# MSPM0G320X register map
Vendor: Texas Instruments; File version: Revised: 2025-10-06 10:58:04
CPU: CM0 r0p1, little endian, MPU, no FPU, 3 interrupt priority bits
Registers are 32-bit, read-write, reset 0x0 unless marked. A register's access mark holds for its fields unless they carry their own. Offsets are from the block's base; [hi:lo] are bit positions; lines under a group give offsets from that group; {n}, {i} and the like mark numbered series; 'fields as' and 'values as' point back to an identical list.

## CANFD0 (part 3 of 3) — PERIPHERALREGION
Base 0x40508000
0x6800 CANFD0_PWREN — Power enable
  [0] ENABLE — Enable the power
    0=DISABLE (Disable Power); 1=ENABLE (Enable Power)
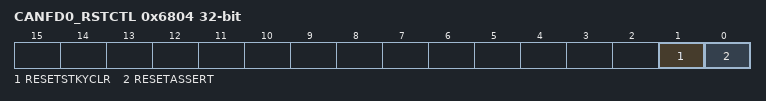
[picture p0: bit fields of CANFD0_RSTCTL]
0x6804 CANFD0_RSTCTL wo — Reset Control
  [1] RESETSTKYCLR — Clear the RESETSTKY bit in the STAT register
    0=NOP (Writing 0 has no effect); 1=CLR (Clear reset sticky bit)
  [0] RESETASSERT — Assert reset to the peripheral
    0=NOP (Writing 0 has no effect); 1=ASSERT (Assert reset)
0x6814 CANFD0_STAT ro — Status Register
  [16] RESETSTKY — This bit indicates, if the peripheral was reset, since this bit was cleared by RESETSTKYCLR in the RSTCTL register
    0=NORES (The peripheral has not been reset since this bit was last cleared by RESETSTKYCLR in the RSTCTL register); 1=RESET (The peripheral was reset since the last bit clear)

## KEYSTORECTL — PERIPHERALREGION
Base 0x400AC000
0x1100 KEYSTORECTL_CFG reset 0x1 — Keystore configuration
  [3:0] NK256 — Number of 256 bit keys to be held in the key-store. Can not exceed the total number of slots present in the hardware / 2. For eg: if SYS_N_SLOTS = 4, then atmost 2 256-bit keys can be held in the key-store. Incorrect setting of this field will be reported via STATUS register
    0=ZERO (No 256-bit keys); 1=ONE (One 256-bit key); 2=TWO (Two 256-bit keys); 3=THREE (Three 256-bit keys); 4=FOUR (Four 256-bit keys)
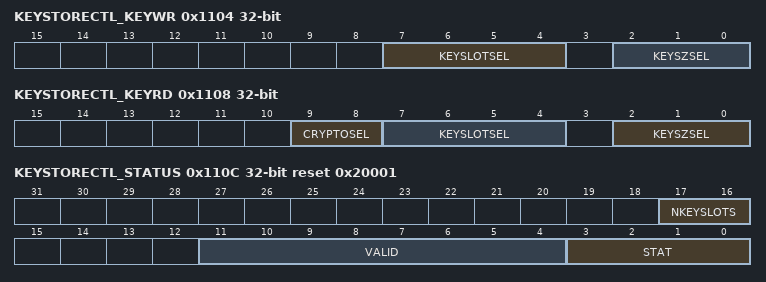
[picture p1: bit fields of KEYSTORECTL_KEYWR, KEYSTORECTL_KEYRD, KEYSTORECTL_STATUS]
0x1104 KEYSTORECTL_KEYWR — Key write configuration
  [7:4] KEYSLOTSEL — Select the key slot to write the key into. NOTE: SW needs to ensure that it is writing to the correct slots. The slot numbering is from 0 through SYS_N_SLOTS-1. Each slot is a 128-bit slot. Therefore, when writing a 256-bit key, two slots will need to budgeted. The selected slot for the 256-bit key needs to be an even numbered slot (eg: 0 or 2). Also all the 256-bit keys need to be stored in lower numbered slots and 128-bit keys stored in higher numbered slots.
    {v}=SLOT{v} (v=0..7)
  [2:0] KEYSZSEL — Key size selection. Selection of 128 or 256 bit keys
    0=K256 (256 bit key); 1=K128 (128 bit key)
0x1108 KEYSTORECTL_KEYRD — Key read configuration
  [9:8] CRYPTOSEL — Crypto engine selector
    0=AES (Transfer key to AES)
  [7:4] KEYSLOTSEL — Select the key slot to read the key from. NOTE: SW needs to ensure that it is reading from the correct slots. The slot numbering is from 0 through SYS_N_SLOTS-1. Each slot is a 128-bit slot. Therefore, when reading a 256-bit key, two adjacent slots will be read. For a 256-bit key, an even numbered slot index must be specified.
  [2:0] KEYSZSEL — Key size selection. Selection of 128 or 256 bit keys
    0=K256 (256 bit key); 1=K128 (128 bit key)
0x110C KEYSTORECTL_STATUS ro reset 0x20001 — Status
  [17:16] NKEYSLOTS — Size of keystorage: Number of 128-bit key slots
    0=TWO (Two slots); 1=THREE (Three slots); 2=FOUR (Four slots)
  [11:4] VALID — Bitvector of valid bits to indicate which slots have been configured
  [3:0] STAT — Status information
    0=VALID (Valid configuration); 1=NO_CFG (Key-store has not been configured. NK256 has not been set.); 2=INVALID_NK256 (Invalid value for NK256 field in CFG.); 3=BUSY_RECEIVE (Busy receiving a key deposit); 4=BUSY_TRANSMIT (Busy transmitting a key to a crypto engine); 5=INVALID_KEYSLOTSELW (Invalid keyslot selection for writing); 6=INVALID_KEYSLOTSELR (Invalid keyslot selection for reading)
0x1110 KEYSTORECTL_KEYIN wo — Input key
0x1114 KEYSTORECTL_KEYLOCK — Keylock
  [7:0] LOCKBIT — Bitvector of lock bits to lock certain slots from being used by application.

## CPUSS — CPUSSMMR
Base 0x40400000
0x10E0 CPUSS_EVT_MODE ro — Event Mode
  [1:0] INT_CFG — Event line mode select
    0=DISABLE (The interrupt or event line is disabled.); 1=SOFTWARE (Event handled by software. Software must clear the associated RIS flag.); 2=HARDWARE (Event handled by hardware. The hardware (another module) clears automatically the associated RIS flag.)
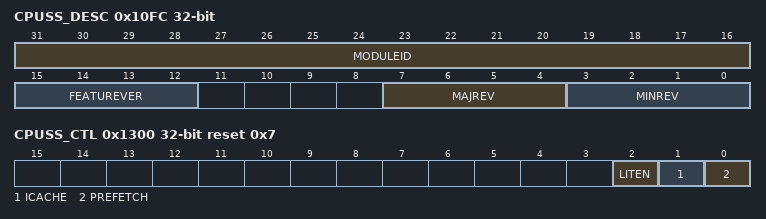
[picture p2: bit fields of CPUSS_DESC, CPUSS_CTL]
0x10FC CPUSS_DESC ro — Module Description
  [31:16] MODULEID — Module identification contains a unique peripheral identification number. The assignments are maintained in a central database for all of the platform modules to ensure uniqueness.
  [15:12] FEATUREVER — Feature Set for the module *instance*
  [7:4] MAJREV — Major rev of the IP
  [3:0] MINREV — Minor rev of the IP
{0x1100+0x2C*i} CPUSS_CPU_INT_GROUP0[{i}] (i=0..0) group
  0x00 CPUSS_CPU_INT_GROUP0_IIDX ro — Interrupt index
    [7:0] STAT — Interrupt index status
      0=NO_INTR (No pending interrupt); {v}=INT{v-1} (Interrupt {v-1}) (v=1..8)
  0x08 CPUSS_CPU_INT_GROUP0_IMASK ro reset 0xFF — Interrupt mask
    [7:0] INT — Masks the corresponding interrupt
      1=Interrupt 0; 2=Interrupt 1; 4=Interrupt 2; 8=Interrupt 3; 16=Interrupt 4; 32=Interrupt 5; 64=Interrupt 6; 128=Interrupt 7
  0x10 CPUSS_CPU_INT_GROUP0_RIS ro — Raw interrupt status
    [7:0] INT — Raw interrupt status for INT
      values as CPUSS_CPU_INT_GROUP0[0].CPUSS_CPU_INT_GROUP0_IMASK.INT
  0x18 CPUSS_CPU_INT_GROUP0_MIS ro — Masked interrupt status
    [7:0] INT — Masked interrupt status for INT0
      values as CPUSS_CPU_INT_GROUP0[0].CPUSS_CPU_INT_GROUP0_IMASK.INT
  0x20 CPUSS_CPU_INT_GROUP0_ISET wo — Interrupt set
    [7:0] INT — Sets INT in RIS register
      values as CPUSS_CPU_INT_GROUP0[0].CPUSS_CPU_INT_GROUP0_IMASK.INT
  0x28 CPUSS_CPU_INT_GROUP0_ICLR wo — Interrupt clear
    [7:0] INT — Clears INT in RIS register
      values as CPUSS_CPU_INT_GROUP0[0].CPUSS_CPU_INT_GROUP0_IMASK.INT
{0x1130+0x2C*i} CPUSS_CPU_INT_GROUP1[{i}] (i=0..0) group
  0x00 CPUSS_CPU_INT_GROUP1_IIDX ro — Interrupt index
    fields as CPUSS_CPU_INT_GROUP0[0].CPUSS_CPU_INT_GROUP0_IIDX
  0x08 CPUSS_CPU_INT_GROUP1_IMASK ro reset 0xFF — Interrupt mask
    fields as CPUSS_CPU_INT_GROUP0[0].CPUSS_CPU_INT_GROUP0_IMASK
  0x10 CPUSS_CPU_INT_GROUP1_RIS ro — Raw interrupt status
    fields as CPUSS_CPU_INT_GROUP0[0].CPUSS_CPU_INT_GROUP0_RIS
  0x18 CPUSS_CPU_INT_GROUP1_MIS ro — Masked interrupt status
    fields as CPUSS_CPU_INT_GROUP0[0].CPUSS_CPU_INT_GROUP0_MIS
  0x20 CPUSS_CPU_INT_GROUP1_ISET wo — Interrupt set
    fields as CPUSS_CPU_INT_GROUP0[0].CPUSS_CPU_INT_GROUP0_ISET
  0x28 CPUSS_CPU_INT_GROUP1_ICLR wo — Interrupt clear
    fields as CPUSS_CPU_INT_GROUP0[0].CPUSS_CPU_INT_GROUP0_ICLR
0x1300 CPUSS_CTL reset 0x7 — Prefetch/Cache control
  [2] LITEN — Literal caching and prefetch enable. This bit is a subset of ICACHE/PREFETCH bit i.e. literal caching or literal prefetching will only happen if ICACHE or PREFETCH bits have been set respectively When enabled, the cache and prefetcher structures inside CPUSS will cache and prefetch literals When disabled, the cache and prefetcher structures inside CPUSS will not cache and prefetch literals
    0=DISABLE (Literal caching disabled); 1=ENABLE (Literal caching enabled)
  [1] ICACHE — Used to enable/disable Instruction caching on flash access.
    0=DISABLE (Disable instruction caching.); 1=ENABLE (Enable instruction caching.)
  [0] PREFETCH — Used to enable/disable instruction prefetch to Flash.
    0=DISABLE (Disable instruction prefetch.); 1=ENABLE (Enable instruction prefetch.)
